# GTC_GTC_CFG3_00AB0000h register map
Vendor: Texas Instruments
Peripheral module from a debugger description file (folder am62L).
Registers are 32-bit, read-only, reset 0x0 unless marked. A register's access mark holds for its fields unless they carry their own. Offsets are as the file gives them; lines under a group give offsets from that group; [hi:lo] are bit positions; {n}, {i} and the like mark numbered series; 'fields as' and 'values as' point back to an identical list; <NAME> marks a mode.

## GTC_CFG3
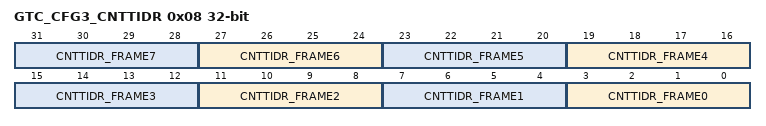
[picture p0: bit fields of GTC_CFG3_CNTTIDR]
0x08 GTC_CFG3_CNTTIDR
  [4n+3:4n] CNTTIDR_FRAME{n} (n=0..7) — Indicates the features of timer frame{n}. Each 4 bit field has the following meaning: Reset Source: mod_por_rst_n
